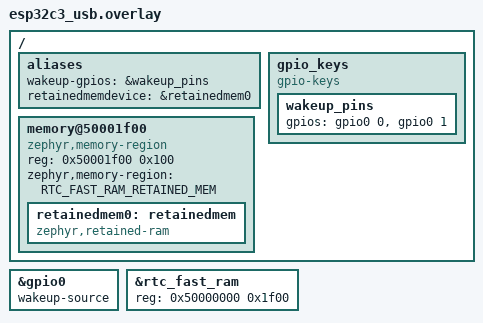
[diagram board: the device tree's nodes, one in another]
/*
 * Copyright (c) 2022-2026 Espressif Systems (Shanghai) Co., Ltd.
 *
 * SPDX-License-Identifier: Apache-2.0
 */

/ {
	aliases {
		/* On ESP32-C3, only GPIO0~5 can be used
		 * as wake-up sources
		 */
		wakeup-gpios = &wakeup_pins;
		retainedmemdevice = &retainedmem0;
	};

	gpio_keys {
		compatible = "gpio-keys";

		wakeup_pins: wakeup_pins {
			gpios = <&gpio0 0 (GPIO_PULL_DOWN | GPIO_ACTIVE_HIGH | GPIO_INT_WAKEUP)>,
				<&gpio0 1 (GPIO_PULL_DOWN | GPIO_ACTIVE_HIGH | GPIO_INT_WAKEUP)>;
		};
	};

	memory@50001f00 {
		compatible = "zephyr,memory-region", "mmio-sram";
		reg = <0x50001f00 0x100>;
		zephyr,memory-region = "RTC_FAST_RAM_RETAINED_MEM";
		status = "okay";

		retainedmem0: retainedmem {
			compatible = "zephyr,retained-ram";
			status = "okay";
		};
	};
};

&gpio0 {
	/* Configure device as wakeup source */
	wakeup-source;
};

&rtc_fast_ram {
	/* Shrink rtc_fast_ram size to avoid overlap with retained memory region:
	 * 8KB - 256 = 0x1f00
	 */
	reg = <0x50000000 0x1f00>;
};
